AUTOSAR XML (schema 4-0-3)
package /ComponentTypes
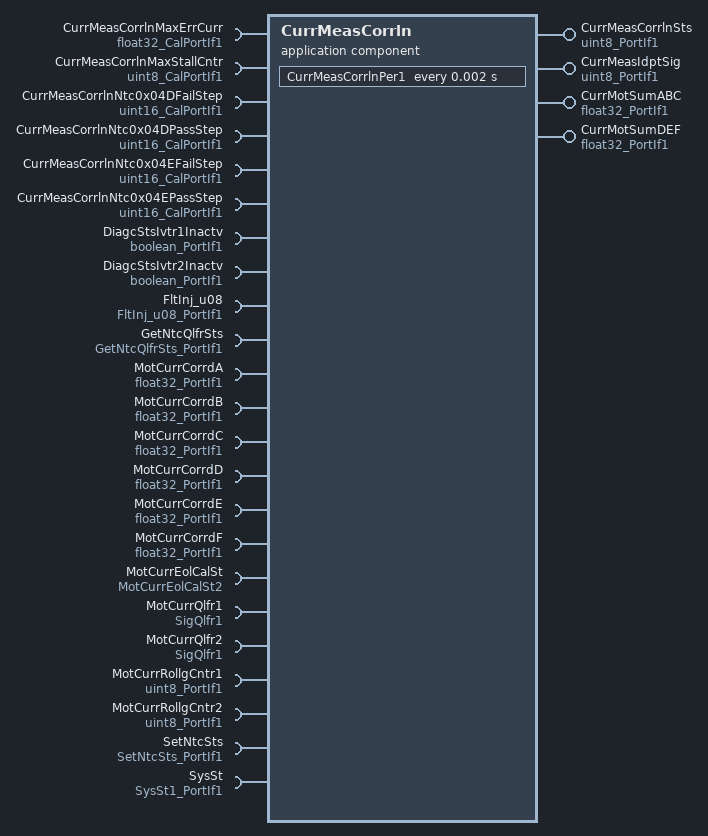
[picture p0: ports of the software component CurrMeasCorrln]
  application sw component type CurrMeasCorrln
    4 x provide port:
      CurrMeasCorrlnSts: nonqueued-sender-com-spec{data-element=Val, init-value=63}, provided-interface=uint8_PortIf1
      CurrMeasIdptSig: nonqueued-sender-com-spec{data-element=Val, init-value=2}, provided-interface=uint8_PortIf1
      CurrMotSumABC: nonqueued-sender-com-spec{data-element=Val, init-value=0}, provided-interface=float32_PortIf1
      CurrMotSumDEF: nonqueued-sender-com-spec{data-element=Val, init-value=0}, provided-interface=float32_PortIf1
    23 x require port:
      CurrMeasCorrlnMaxErrCurr: parameter-require-com-spec{init-value=12, parameter=Val}, required-interface=float32_CalPortIf1
      CurrMeasCorrlnMaxStallCntr: parameter-require-com-spec{init-value=200, parameter=Val}, required-interface=uint8_CalPortIf1
      CurrMeasCorrlnNtc0x04DFailStep: parameter-require-com-spec{init-value=512, parameter=Val}, required-interface=uint16_CalPortIf1
      CurrMeasCorrlnNtc0x04DPassStep: parameter-require-com-spec{init-value=512, parameter=Val}, required-interface=uint16_CalPortIf1
      CurrMeasCorrlnNtc0x04EFailStep: parameter-require-com-spec{init-value=512, parameter=Val}, required-interface=uint16_CalPortIf1
      CurrMeasCorrlnNtc0x04EPassStep: parameter-require-com-spec{init-value=512, parameter=Val}, required-interface=uint16_CalPortIf1
      DiagcStsIvtr1Inactv: nonqueued-receiver-com-spec{data-element=Logl, filter=data-filter-type=ALWAYS, init-value=0}, required-interface=boolean_PortIf1
      DiagcStsIvtr2Inactv: nonqueued-receiver-com-spec{data-element=Logl, filter=data-filter-type=ALWAYS, init-value=0}, required-interface=boolean_PortIf1
      FltInj_u08: required-interface=FltInj_u08_PortIf1
      GetNtcQlfrSts: required-interface=GetNtcQlfrSts_PortIf1
      MotCurrCorrdA: nonqueued-receiver-com-spec{data-element=Val, filter=data-filter-type=ALWAYS, init-value=0}, required-interface=float32_PortIf1
      MotCurrCorrdB: nonqueued-receiver-com-spec{data-element=Val, filter=data-filter-type=ALWAYS, init-value=0}, required-interface=float32_PortIf1
      MotCurrCorrdC: nonqueued-receiver-com-spec{data-element=Val, filter=data-filter-type=ALWAYS, init-value=0}, required-interface=float32_PortIf1
      MotCurrCorrdD: nonqueued-receiver-com-spec{data-element=Val, filter=data-filter-type=ALWAYS, init-value=0}, required-interface=float32_PortIf1
      MotCurrCorrdE: nonqueued-receiver-com-spec{data-element=Val, filter=data-filter-type=ALWAYS, init-value=0}, required-interface=float32_PortIf1
      MotCurrCorrdF: nonqueued-receiver-com-spec{data-element=Val, filter=data-filter-type=ALWAYS, init-value=0}, required-interface=float32_PortIf1
      MotCurrEolCalSt: nonqueued-receiver-com-spec{data-element=Val, filter=data-filter-type=ALWAYS, init-value=0}, required-interface=MotCurrEolCalSt2
      MotCurrQlfr1: nonqueued-receiver-com-spec{data-element=Val, filter=data-filter-type=ALWAYS, init-value=0}, required-interface=SigQlfr1
      MotCurrQlfr2: nonqueued-receiver-com-spec{data-element=Val, filter=data-filter-type=ALWAYS, init-value=0}, required-interface=SigQlfr1
      MotCurrRollgCntr1: nonqueued-receiver-com-spec{data-element=Val, filter=data-filter-type=ALWAYS, init-value=0}, required-interface=uint8_PortIf1
      MotCurrRollgCntr2: nonqueued-receiver-com-spec{data-element=Val, filter=data-filter-type=ALWAYS, init-value=0}, required-interface=uint8_PortIf1
      SetNtcSts: required-interface=SetNtcSts_PortIf1
      SysSt: nonqueued-receiver-com-spec{data-element=Val, filter=data-filter-type=ALWAYS, init-value=3}, required-interface=SysSt1_PortIf1
    behavior CurrMeasCorrln_InternalBehavior: data-type-mapping=Nexteer
      ar-typed-per-instance-memorys:
        4 x data, all with sw-calibration-access=READ-ONLY, type=uint8:
          CurrMeasCorrlnSens0RollgCntPrev
          CurrMeasCorrlnSens0StallCntPrev
          CurrMeasCorrlnSens1RollgCntPrev
          CurrMeasCorrlnSens1StallCntPrev
      timing event TMT_CurrMeasCorrlnPer1: start-on-event=CurrMeasCorrlnPer1, period=0.002
      runnable CurrMeasCorrlnPer1
        data-receive-point-by-arguments:
          14 x access:
            REC_DiagcStsIvtr1Inactv_Logl: accessed-variable=DiagcStsIvtr1Inactv.Logl
            REC_DiagcStsIvtr2Inactv_Logl: accessed-variable=DiagcStsIvtr2Inactv.Logl
            REC_MotCurrCorrdA_Val: accessed-variable=MotCurrCorrdA.Val
            REC_MotCurrCorrdB_Val: accessed-variable=MotCurrCorrdB.Val
            REC_MotCurrCorrdC_Val: accessed-variable=MotCurrCorrdC.Val
            REC_MotCurrCorrdD_Val: accessed-variable=MotCurrCorrdD.Val
            REC_MotCurrCorrdE_Val: accessed-variable=MotCurrCorrdE.Val
            REC_MotCurrCorrdF_Val: accessed-variable=MotCurrCorrdF.Val
            REC_MotCurrEolCalSt_Val: accessed-variable=MotCurrEolCalSt.Val
            REC_MotCurrQlfr1_Val: accessed-variable=MotCurrQlfr1.Val
            REC_MotCurrQlfr2_Val: accessed-variable=MotCurrQlfr2.Val
            REC_MotCurrRollgCntr1_Val: accessed-variable=MotCurrRollgCntr1.Val
            REC_MotCurrRollgCntr2_Val: accessed-variable=MotCurrRollgCntr2.Val
            REC_SysSt_Val: accessed-variable=SysSt.Val
        data-send-points:
          4 x access:
            SEND_CurrMeasCorrlnSts_Val: accessed-variable=CurrMeasCorrlnSts.Val
            SEND_CurrMeasIdptSig_Val: accessed-variable=CurrMeasIdptSig.Val
            SEND_CurrMotSumABC_Val: accessed-variable=CurrMotSumABC.Val
            SEND_CurrMotSumDEF_Val: accessed-variable=CurrMotSumDEF.Val
        sync call SC_FltInj_u08_Oper: operation=FltInj_u08.Oper, timeout=0
        sync call SC_GetNtcQlfrSts_Oper: operation=GetNtcQlfrSts.Oper, timeout=0
        sync call SC_SetNtcSts_Oper: operation=SetNtcSts.Oper, timeout=0
  swc implementation CurrMeasCorrln_Implementation: behavior=CurrMeasCorrln_InternalBehavior
    code-descriptors:
      code Default: artifact-descriptors=autosar-engineering-object={short-label=Default, category=SWSRC}
